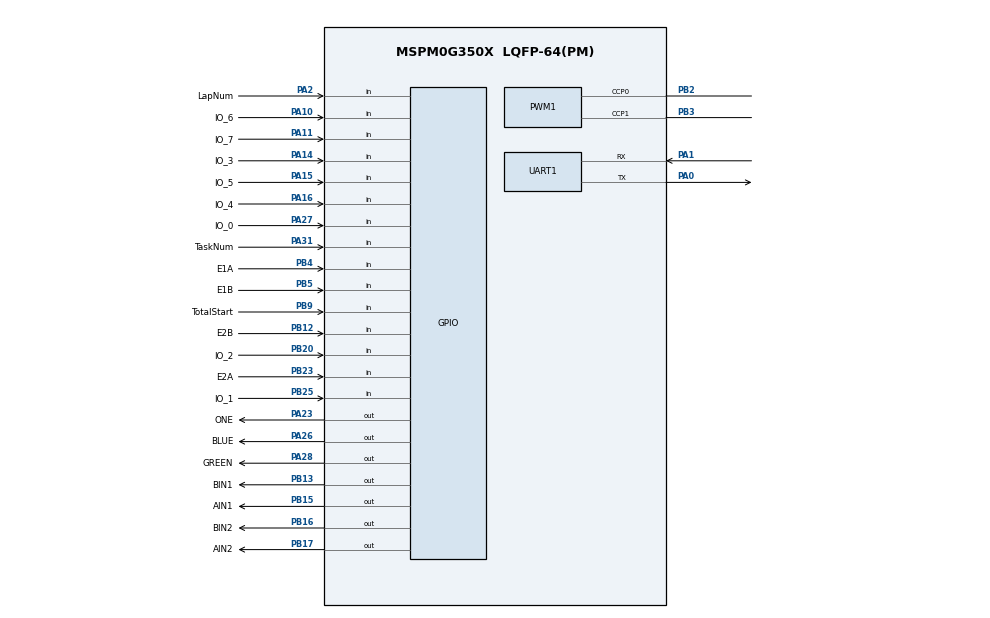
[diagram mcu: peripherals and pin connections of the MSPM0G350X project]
/**
 * @cliArgs --device "MSPM0G350X" --part "Default" --package "LQFP-64(PM)" --product "mspm0_sdk@2.03.00.07"
 * @versions {"tool":"1.22.0+3893"}
 */

/**
 * Import the modules used in this configuration.
 */
const GPIO    = scripting.addModule("/ti/driverlib/GPIO", {}, false);
const GPIO1   = GPIO.addInstance();
const GPIO2   = GPIO.addInstance();
const GPIO3   = GPIO.addInstance();
const GPIO4   = GPIO.addInstance();
const GPIO5   = GPIO.addInstance();
const GPIO6   = GPIO.addInstance();
const GPIO7   = GPIO.addInstance();
const GPIO8   = GPIO.addInstance();
const PWM     = scripting.addModule("/ti/driverlib/PWM", {}, false);
const PWM1    = PWM.addInstance();
const SYSCTL  = scripting.addModule("/ti/driverlib/SYSCTL");
const SYSTICK = scripting.addModule("/ti/driverlib/SYSTICK");
const TIMER   = scripting.addModule("/ti/driverlib/TIMER", {}, false);
const TIMER1  = TIMER.addInstance();
const TIMER2  = TIMER.addInstance();
const UART    = scripting.addModule("/ti/driverlib/UART", {}, false);
const UART1   = UART.addInstance();

/**
 * Write custom configuration values to the imported modules.
 */
const gate7  = system.clockTree["MFCLKGATE"];
gate7.enable = true;

/* ===================== LED ===================== */
GPIO1.port                               = "PORTA";
GPIO1.$name                              = "LED";
GPIO1.associatedPins.create(2);
GPIO1.associatedPins[0].internalResistor = "PULL_DOWN";
GPIO1.associatedPins[0].assignedPin      = "26";
GPIO1.associatedPins[0].$name            = "BLUE";
GPIO1.associatedPins[0].pin.$assign      = "PA26";
GPIO1.associatedPins[1].assignedPin      = "28";  // GREEN 从 PA27 挪到 PA28（原 PA27 给灰度 HD1）
GPIO1.associatedPins[1].$name            = "GREEN";
GPIO1.associatedPins[1].pin.$assign      = "PA28";

const Board = scripting.addModule("/ti/driverlib/Board", {}, false);

/* ===================== KEY ===================== */
GPIO2.$name                              = "KEY";
GPIO2.associatedPins.create(3);
GPIO2.associatedPins[0].direction        = "INPUT";
GPIO2.associatedPins[0].internalResistor = "PULL_UP";
GPIO2.associatedPins[0].inputFilter      = "8_CYCLES";
GPIO2.associatedPins[0].assignedPin      = "02";
GPIO2.associatedPins[0].assignedPort     = "PORTA";
GPIO2.associatedPins[0].$name            = "LapNum";
GPIO2.associatedPins[0].pin.$assign      = "PA2";
GPIO2.associatedPins[1].direction        = "INPUT";
GPIO2.associatedPins[1].internalResistor = "PULL_UP";
GPIO2.associatedPins[1].inputFilter      = "8_CYCLES";
GPIO2.associatedPins[1].assignedPin      = "31";  // TaskNum 保持 PA31（HD6 改到 PA15 避让）
GPIO2.associatedPins[1].assignedPort     = "PORTA";
GPIO2.associatedPins[1].$name            = "TaskNum";
GPIO2.associatedPins[1].pin.$assign      = "PA31";
GPIO2.associatedPins[2].direction        = "INPUT";
GPIO2.associatedPins[2].assignedPort     = "PORTB";
GPIO2.associatedPins[2].assignedPin      = "09";
GPIO2.associatedPins[2].internalResistor = "PULL_UP";
GPIO2.associatedPins[2].$name            = "TotalStart";
GPIO2.associatedPins[2].pin.$assign      = "PB9";

/* ===================== BEEP ===================== */
GPIO3.port                           = "PORTA";
GPIO3.$name                          = "BEEP";
GPIO3.associatedPins[0].assignedPin  = "23";
GPIO3.associatedPins[0].initialValue = "SET";
GPIO3.associatedPins[0].$name        = "ONE";
GPIO3.associatedPins[0].pin.$assign  = "PA23";

/* ===================== Motor_left (TB6612 A通道) ===================== */
GPIO4.$name                          = "Motor_left";
GPIO4.port                           = "PORTB";
GPIO4.associatedPins.create(2);
GPIO4.associatedPins[0].initialValue = "SET";
GPIO4.associatedPins[0].$name        = "AIN1";
GPIO4.associatedPins[0].assignedPin  = "15";
GPIO4.associatedPins[0].pin.$assign  = "PB15";
GPIO4.associatedPins[1].$name        = "AIN2";
GPIO4.associatedPins[1].initialValue = "SET";
GPIO4.associatedPins[1].assignedPin  = "17";
GPIO4.associatedPins[1].pin.$assign  = "PB17";

/* ===================== Motor_right (TB6612 B通道) ===================== */
GPIO5.$name                          = "Motor_right";
GPIO5.associatedPins.create(2);
GPIO5.associatedPins[0].$name        = "BIN1";
GPIO5.associatedPins[0].initialValue = "SET";
GPIO5.associatedPins[0].assignedPort = "PORTB";
GPIO5.associatedPins[0].assignedPin  = "13";
GPIO5.associatedPins[0].pin.$assign  = "PB13";
GPIO5.associatedPins[1].$name        = "BIN2";
GPIO5.associatedPins[1].initialValue = "SET";
GPIO5.associatedPins[1].assignedPort = "PORTB";
GPIO5.associatedPins[1].assignedPin  = "16";
GPIO5.associatedPins[1].pin.$assign  = "PB16";

/* ===================== Encoder_left (GPIOB) ===================== */
GPIO6.$name                               = "Encoder_left";
GPIO6.port                                = "PORTB";
GPIO6.associatedPins.create(2);
GPIO6.associatedPins[0].direction         = "INPUT";
GPIO6.associatedPins[0].internalResistor   = "PULL_UP";
GPIO6.associatedPins[0].$name             = "E1A";
GPIO6.associatedPins[0].assignedPin       = "4";
GPIO6.associatedPins[0].interruptEn       = true;
GPIO6.associatedPins[0].interruptPriority = "0";
GPIO6.associatedPins[0].polarity          = "RISE";
GPIO6.associatedPins[0].pin.$assign       = "PB4";
GPIO6.associatedPins[1].$name             = "E1B";
GPIO6.associatedPins[1].direction         = "INPUT";
GPIO6.associatedPins[1].internalResistor   = "PULL_UP";
GPIO6.associatedPins[1].assignedPin       = "5";
GPIO6.associatedPins[1].interruptEn       = true;
GPIO6.associatedPins[1].interruptPriority = "0";
GPIO6.associatedPins[1].polarity          = "RISE";
GPIO6.associatedPins[1].pin.$assign       = "PB5";

/* ===================== Encoder_right (GPIOB) ===================== */
GPIO7.$name                               = "Encoder_right";
GPIO7.port                                = "PORTB";
GPIO7.associatedPins.create(2);
GPIO7.associatedPins[0].$name             = "E2A";
GPIO7.associatedPins[0].direction         = "INPUT";
GPIO7.associatedPins[0].assignedPin       = "23";
GPIO7.associatedPins[0].interruptEn       = true;
GPIO7.associatedPins[0].interruptPriority = "0";
GPIO7.associatedPins[0].polarity          = "RISE";
GPIO7.associatedPins[0].pin.$assign       = "PB23";
GPIO7.associatedPins[1].$name             = "E2B";
GPIO7.associatedPins[1].direction         = "INPUT";
GPIO7.associatedPins[1].internalResistor   = "PULL_UP";
GPIO7.associatedPins[1].assignedPin       = "12";
GPIO7.associatedPins[1].interruptEn       = true;
GPIO7.associatedPins[1].interruptPriority = "0";
GPIO7.associatedPins[1].polarity          = "RISE";
GPIO7.associatedPins[1].pin.$assign       = "PB12";

/* ===================== Gray (8路一字排开, 跨PORTA/PORTB, 靠单脚assignedPort) ===================== */
GPIO8.$name                         = "Gray";
GPIO8.associatedPins.create(8);
GPIO8.associatedPins[0].direction   = "INPUT";
GPIO8.associatedPins[0].assignedPort = "PORTA";
GPIO8.associatedPins[0].assignedPin = "27";  // HD1
GPIO8.associatedPins[0].$name       = "IO_0";
GPIO8.associatedPins[0].pin.$assign = "PA27";
GPIO8.associatedPins[1].direction   = "INPUT";
GPIO8.associatedPins[1].assignedPort = "PORTB";
GPIO8.associatedPins[1].assignedPin = "25";  // HD2
GPIO8.associatedPins[1].$name       = "IO_1";
GPIO8.associatedPins[1].pin.$assign = "PB25";
GPIO8.associatedPins[2].direction   = "INPUT";
GPIO8.associatedPins[2].assignedPort = "PORTB";
GPIO8.associatedPins[2].assignedPin = "20";  // HD3
GPIO8.associatedPins[2].$name       = "IO_2";
GPIO8.associatedPins[2].pin.$assign = "PB20";
GPIO8.associatedPins[3].direction   = "INPUT";
GPIO8.associatedPins[3].assignedPort = "PORTA";
GPIO8.associatedPins[3].assignedPin = "14";  // HD4
GPIO8.associatedPins[3].$name       = "IO_3";
GPIO8.associatedPins[3].pin.$assign = "PA14";
GPIO8.associatedPins[4].direction   = "INPUT";
GPIO8.associatedPins[4].assignedPort = "PORTA";
GPIO8.associatedPins[4].assignedPin = "16";  // HD5
GPIO8.associatedPins[4].$name       = "IO_4";
GPIO8.associatedPins[4].pin.$assign = "PA16";
GPIO8.associatedPins[5].direction   = "INPUT";
GPIO8.associatedPins[5].assignedPort = "PORTA";
GPIO8.associatedPins[5].assignedPin = "15";  // HD6 (从 PA31 挪到 PA15 避让 KEY_TaskNum)
GPIO8.associatedPins[5].$name       = "IO_5";
GPIO8.associatedPins[5].pin.$assign = "PA15";
GPIO8.associatedPins[6].direction   = "INPUT";
GPIO8.associatedPins[6].assignedPort = "PORTA";
GPIO8.associatedPins[6].assignedPin = "10";  // HD7
GPIO8.associatedPins[6].$name       = "IO_6";
GPIO8.associatedPins[6].pin.$assign = "PA10";
GPIO8.associatedPins[7].direction   = "INPUT";
GPIO8.associatedPins[7].assignedPort = "PORTA";
GPIO8.associatedPins[7].assignedPin = "11";  // HD8
GPIO8.associatedPins[7].$name       = "IO_7";
GPIO8.associatedPins[7].pin.$assign = "PA11";

/* ===================== PWM (TIMG6, 保留 PB2/PB3 已验证通道) ===================== */
/* 注意：用户原接线 PWMA=A17/PWMB=B18；若驱动板已固定，可在 GUI 里把
   ccp0Pin/ccp1Pin 改为 PA17/PB18 再 Generate（SysConfig 会校验能否路由）。 */
PWM1.$name                              = "PWM";
PWM1.clockDivider                       = 8;
PWM1.pwmMode                            = "EDGE_ALIGN_UP";
PWM1.timerStartTimer                    = true;
PWM1.clockPrescale                      = 4;
PWM1.peripheral.$assign                 = "TIMG6";
PWM1.peripheral.ccp0Pin.$assign         = "PB2";
PWM1.peripheral.ccp1Pin.$assign         = "PB3";
PWM1.PWM_CHANNEL_0.$name                = "ti_driverlib_pwm_PWMTimerCC0";
PWM1.PWM_CHANNEL_1.$name                = "ti_driverlib_pwm_PWMTimerCC1";
PWM1.ccp0PinConfig.direction            = scripting.forceWrite("OUTPUT");
PWM1.ccp0PinConfig.hideOutputInversion  = scripting.forceWrite(false);
PWM1.ccp0PinConfig.onlyInternalResistor = scripting.forceWrite(false);
PWM1.ccp0PinConfig.passedPeripheralType = scripting.forceWrite("Digital");
PWM1.ccp0PinConfig.$name                = "ti_driverlib_gpio_GPIOPinGeneric2";
PWM1.ccp1PinConfig.direction            = scripting.forceWrite("OUTPUT");
PWM1.ccp1PinConfig.hideOutputInversion  = scripting.forceWrite(false);
PWM1.ccp1PinConfig.onlyInternalResistor = scripting.forceWrite(false);
PWM1.ccp1PinConfig.passedPeripheralType = scripting.forceWrite("Digital");
PWM1.ccp1PinConfig.$name                = "ti_driverlib_gpio_GPIOPinGeneric3";

SYSCTL.forceDefaultClkConfig = true;
SYSCTL.clockTreeEn           = true;

SYSTICK.periodEnable      = true;
SYSTICK.systickEnable     = true;
SYSTICK.interruptPriority = "0";
SYSTICK.period            = 32;

TIMER1.$name              = "TIMER_0";
TIMER1.timerClkDiv        = 8;
TIMER1.timerClkPrescale   = 100;
TIMER1.timerMode          = "PERIODIC";
TIMER1.interrupts         = ["ZERO"];
TIMER1.timerStartTimer    = true;
TIMER1.timerPeriod        = "10ms";
TIMER1.interruptPriority  = "0";
TIMER1.peripheral.$assign = "TIMA0";

TIMER2.$name              = "TIMER_1";
TIMER2.timerStartTimer    = true;
TIMER2.timerMode          = "PERIODIC";
TIMER2.timerClkDiv        = 8;
TIMER2.timerClkPrescale   = 100;
TIMER2.interrupts         = ["LOAD"];
TIMER2.interruptPriority  = "1";
TIMER2.timerPeriod        = "10ms";
TIMER2.peripheral.$assign = "TIMG0";

UART1.$name                    = "UART_0";
UART1.targetBaudRate           = 115200;
UART1.enabledInterrupts        = ["RX"];
UART1.peripheral.$assign       = "UART0";
UART1.peripheral.rxPin.$assign = "PA1";
UART1.peripheral.txPin.$assign = "PA0";
UART1.txPinConfig.$name        = "ti_driverlib_gpio_GPIOPinGeneric4";
UART1.rxPinConfig.$name        = "ti_driverlib_gpio_GPIOPinGeneric5";
